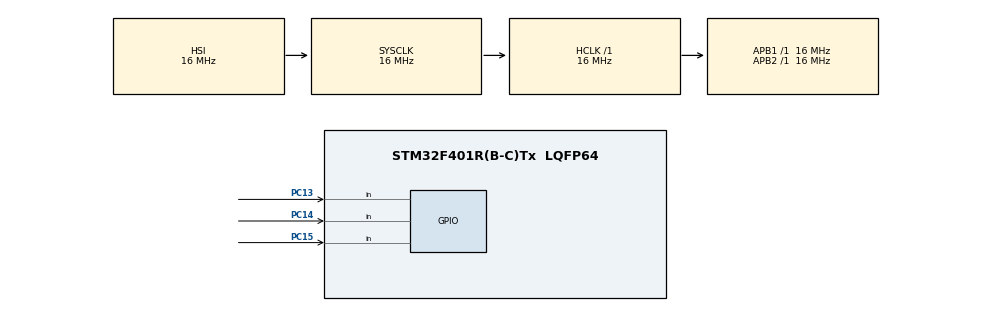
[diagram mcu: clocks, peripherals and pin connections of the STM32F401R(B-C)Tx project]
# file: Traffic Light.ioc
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FREERTOS.Tasks01=defaultTask,24,128,StartDefaultTask,Default,NULL,Dynamic,NULL,NULL
FREERTOS.configUSE_NEWLIB_REENTRANT=1
Mcu.Family=STM32F4
Mcu.Name=STM32F401R(B-C)Tx
Mcu.Package=LQFP64
NVIC.PriorityGroup=NVIC_PRIORITYGROUP_4
NVIC.TIM2_IRQn=true\:15\:0\:false\:false\:true\:false\:false\:true\:true
NVIC.TimeBase=TIM2_IRQn
NVIC.TimeBaseIP=TIM2
PC13-ANTI_TAMP.GPIO_PuPd=GPIO_PULLDOWN
PC13-ANTI_TAMP.Signal=GPIO_Input
PC14-OSC32_IN.GPIO_PuPd=GPIO_PULLDOWN
PC14-OSC32_IN.Signal=GPIO_Input
PC15-OSC32_OUT.GPIO_PuPd=GPIO_PULLDOWN
PC15-OSC32_OUT.Signal=GPIO_Input
ProjectManager.HeapSize=0x200
ProjectManager.StackSize=0x400
ProjectManager.TargetToolchain=STM32CubeIDE
RCC.AHBFreq_Value=16000000
RCC.APB1Freq_Value=16000000
RCC.APB1TimFreq_Value=16000000
RCC.APB2Freq_Value=16000000
RCC.APB2TimFreq_Value=16000000
RCC.CortexFreq_Value=16000000
RCC.HCLKFreq_Value=16000000
RCC.HSE_VALUE=25000000
RCC.HSI_VALUE=16000000
RCC.LSE_VALUE=32768
RCC.SYSCLKFreq_VALUE=16000000
RCC.VCOOutputFreq_Value=192000000
VP_FREERTOS_VS_CMSIS_V2.Mode=CMSIS_V2
VP_SYS_VS_tim2.Mode=TIM2
board=custom

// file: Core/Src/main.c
/* USER CODE BEGIN Header */
/**
  ******************************************************************************
  * @file           : main.c
  * @brief          : Main program body
  ******************************************************************************
  * @attention
  *
  * Copyright (c) 2024 STMicroelectronics.
  * All rights reserved.
  *
  * This software is licensed under terms that can be found in the LICENSE file
  * in the root directory of this software component.
  * If no LICENSE file comes with this software, it is provided AS-IS.
  *
  ******************************************************************************
  */
/* USER CODE END Header */
#include "main.h"
#include "cmsis_os.h"

/* USER CODE BEGIN Includes */
#include <LED_interface.h>
#include <SSD_interface.h>
#include <FreeRTOS.h>
#include <task.h>
/* USER CODE END Includes */

/* USER CODE BEGIN PTD */
typedef enum {
	GREEN = 0,
	YELLOW,
	RED,
	MANUAL_YELLOW,
	MANUAL_RED,
	MANUAL_GREEN
} TrafficLightState_t;
/* USER CODE END PTD */

/* USER CODE BEGIN PD */
#define GREEN_LIGHT_DURATION	6000
#define YELLOW_LIGHT_DURATION	2000
#define RED_LIGHT_DURATION		6000
#define GREEN_LED_PIN			GPIO_PIN_11
#define YELLOW_LED_PIN			GPIO_PIN_12
#define RED_LED_PIN				GPIO_PIN_15
#define LED_GPIO				GPIOA
#define MANUAL_MODE_PIN			GPIO_PIN_13
#define RED_MODE_PIN			GPIO_PIN_14
#define GREEN_MODE_PIN			GPIO_PIN_15
#define MANUAL_MODE_PORT		GPIOC
/* USER CODE END PD */

/* Definitions for defaultTask */
osThreadId_t defaultTaskHandle;
const osThreadAttr_t defaultTask_attributes = {
  .name = "defaultTask",
  .stack_size = 128 * 4,
  .priority = (osPriority_t) osPriorityNormal,
};
/* USER CODE BEGIN PV */
uint8_t seconds = 0;
TrafficLightState_t currentState = GREEN;
TaskHandle_t xTrafficLight, xTrafficTimer;
GPIO_PinState xMode = GPIO_PIN_RESET;
GPIO_PinState xRed = GPIO_PIN_RESET;
GPIO_PinState xGreen = GPIO_PIN_RESET;
/* USER CODE END PV */

void SystemClock_Config(void);
static void MX_GPIO_Init(void);
void StartDefaultTask(void *argument);

/* USER CODE BEGIN PFP */
void vTrafficMultiplexTimer(void *pvParameters);
void vTrafficLightTask(void *pvParameters);
void vTrafficTimer(void *pvParameters);
/* USER CODE END PFP */

int main(void)
{

  /* MCU Configuration--------------------------------------------------------*/

  /* Reset of all peripherals, Initializes the Flash interface and the Systick. */
  HAL_Init();

  /* Configure the system clock */
  SystemClock_Config();

  /* Initialize all configured peripherals */
  MX_GPIO_Init();
  /* USER CODE BEGIN 2 */
  LED_voidInit(LED_GPIO, GREEN_LED_PIN);
  LED_voidInit(LED_GPIO, YELLOW_LED_PIN);
  LED_voidInit(LED_GPIO, RED_LED_PIN);
  SSD_voidInit();

  xTaskCreate(vTrafficMultiplexTimer, "Traffic Multiplex", configMINIMAL_STACK_SIZE, NULL, 4, NULL);
  xTaskCreate(vTrafficLightTask, "Traffic Light", configMINIMAL_STACK_SIZE, NULL, 3, xTrafficLight);
  //xTaskCreate(vTrafficTimer, "Traffic Timer", configMINIMAL_STACK_SIZE, NULL, 2, xTrafficTimer);

  vTaskStartScheduler();
  /* USER CODE END 2 */

  /* Init scheduler */
  //osKernelInitialize();

  /* Create the thread(s) */
  /* creation of defaultTask */
  //defaultTaskHandle = osThreadNew(StartDefaultTask, NULL, &defaultTask_attributes);

  /* Start scheduler */
  //osKernelStart();

  /* We should never get here as control is now taken by the scheduler */

  /* Infinite loop */
  while (1)
  {

  }
}

void SystemClock_Config(void)
{
  RCC_OscInitTypeDef RCC_OscInitStruct = {0};
  RCC_ClkInitTypeDef RCC_ClkInitStruct = {0};

  /** Configure the main internal regulator output voltage
  */
  __HAL_RCC_PWR_CLK_ENABLE();
  __HAL_PWR_VOLTAGESCALING_CONFIG(PWR_REGULATOR_VOLTAGE_SCALE2);

  /** Initializes the RCC Oscillators according to the specified parameters
  * in the RCC_OscInitTypeDef structure.
  */
  RCC_OscInitStruct.OscillatorType = RCC_OSCILLATORTYPE_HSI;
  RCC_OscInitStruct.HSIState = RCC_HSI_ON;
  RCC_OscInitStruct.HSICalibrationValue = RCC_HSICALIBRATION_DEFAULT;
  RCC_OscInitStruct.PLL.PLLState = RCC_PLL_NONE;
  if (HAL_RCC_OscConfig(&RCC_OscInitStruct) != HAL_OK)
  {
    Error_Handler();
  }

  /** Initializes the CPU, AHB and APB buses clocks
  */
  RCC_ClkInitStruct.ClockType = RCC_CLOCKTYPE_HCLK|RCC_CLOCKTYPE_SYSCLK
                              |RCC_CLOCKTYPE_PCLK1|RCC_CLOCKTYPE_PCLK2;
  RCC_ClkInitStruct.SYSCLKSource = RCC_SYSCLKSOURCE_HSI;
  RCC_ClkInitStruct.AHBCLKDivider = RCC_SYSCLK_DIV1;
  RCC_ClkInitStruct.APB1CLKDivider = RCC_HCLK_DIV1;
  RCC_ClkInitStruct.APB2CLKDivider = RCC_HCLK_DIV1;

  if (HAL_RCC_ClockConfig(&RCC_ClkInitStruct, FLASH_LATENCY_0) != HAL_OK)
  {
    Error_Handler();
  }
}

static void MX_GPIO_Init(void)
{
  GPIO_InitTypeDef GPIO_InitStruct = {0};

  /* GPIO Ports Clock Enable */
  __HAL_RCC_GPIOC_CLK_ENABLE();

  /*Configure GPIO pins : PC13 PC14 PC15 */
  GPIO_InitStruct.Pin = GPIO_PIN_13|GPIO_PIN_14|GPIO_PIN_15;
  GPIO_InitStruct.Mode = GPIO_MODE_INPUT;
  GPIO_InitStruct.Pull = GPIO_PULLDOWN;
  HAL_GPIO_Init(GPIOC, &GPIO_InitStruct);

}

/* USER CODE BEGIN 4 */

void vTrafficMultiplexTimer(void *pvParameters){
	while(1){
		SSD_voidDisplayMultiplexedNumber((seconds / 2));
		vTaskDelay(pdMS_TO_TICKS(10));
	}

}

void vTrafficTimer(void *pvParameters){
	while (1){
		//if(xMode == GPIO_PIN_RESET){
			seconds++;
			vTaskDelay(pdMS_TO_TICKS(1000));

	}
}

void vTrafficLightTask(void *pvParameters) {

	while (1) {
		xMode = HAL_GPIO_ReadPin(MANUAL_MODE_PORT, MANUAL_MODE_PIN);
		xRed = HAL_GPIO_ReadPin(MANUAL_MODE_PORT, RED_MODE_PIN);
		xGreen = HAL_GPIO_ReadPin(MANUAL_MODE_PORT, GREEN_MODE_PIN);
		if(xMode == 1 && xRed == 1){
			currentState = MANUAL_RED;
		}
		else if (xMode == 1 && xGreen == 1){
			currentState = MANUAL_GREEN;
		}
		else if(xMode == 1){
			currentState = MANUAL_YELLOW;
		}
		else{

		}
		switch (currentState) {
			case GREEN:
			LED_voidOn(LED_GPIO, GREEN_LED_PIN, LED_FORWARD_CONNECTION);
			LED_voidOff(LED_GPIO, RED_LED_PIN, LED_FORWARD_CONNECTION);
			LED_voidOff(LED_GPIO, YELLOW_LED_PIN, LED_FORWARD_CONNECTION);
			if ((GREEN_LIGHT_DURATION / 1000) * 2 == seconds){
				currentState = RED;
				seconds = 0;
			}
			else{
				seconds++;
				vTaskDelay(pdMS_TO_TICKS(500));
			}
			break;

			case YELLOW:
				LED_voidOff(LED_GPIO, GREEN_LED_PIN, LED_FORWARD_CONNECTION);
				LED_voidOff(LED_GPIO, RED_LED_PIN, LED_FORWARD_CONNECTION);
				LED_voidOn(LED_GPIO, YELLOW_LED_PIN, LED_FORWARD_CONNECTION);
				if ((YELLOW_LIGHT_DURATION / 1000) * 2 == seconds){
					currentState = GREEN;
					seconds = 0;
				}
				else{
					seconds++;
					vTaskDelay(pdMS_TO_TICKS(500));
				}
				break;

			case RED:
				LED_voidOff(LED_GPIO, GREEN_LED_PIN, LED_FORWARD_CONNECTION);
				LED_voidOn(LED_GPIO, RED_LED_PIN, LED_FORWARD_CONNECTION);
				LED_voidOff(LED_GPIO, YELLOW_LED_PIN, LED_FORWARD_CONNECTION);
				if ((RED_LIGHT_DURATION / 1000) * 2 == seconds){
					currentState = YELLOW;
					seconds = 0;
				}
				else{
					seconds++;
					vTaskDelay(pdMS_TO_TICKS(500));
				}

				break;
			case MANUAL_RED:
				LED_voidOff(LED_GPIO, GREEN_LED_PIN, LED_FORWARD_CONNECTION);
				LED_voidOn(LED_GPIO, RED_LED_PIN, LED_FORWARD_CONNECTION);
				LED_voidOff(LED_GPIO, YELLOW_LED_PIN, LED_FORWARD_CONNECTION);
				currentState = GREEN;
				seconds = 0;
				break;
			case MANUAL_GREEN:
				LED_voidOn(LED_GPIO, GREEN_LED_PIN, LED_FORWARD_CONNECTION);
				LED_voidOff(LED_GPIO, RED_LED_PIN, LED_FORWARD_CONNECTION);
				LED_voidOff(LED_GPIO, YELLOW_LED_PIN, LED_FORWARD_CONNECTION);
				currentState = GREEN;
				seconds = 0;
				break;
			case MANUAL_YELLOW:
				LED_voidOff(LED_GPIO, GREEN_LED_PIN, LED_FORWARD_CONNECTION);
				LED_voidOff(LED_GPIO, RED_LED_PIN, LED_FORWARD_CONNECTION);
				LED_voidOn(LED_GPIO, YELLOW_LED_PIN, LED_FORWARD_CONNECTION);
				currentState = GREEN;
				seconds = 0;
				break;
			default:
				currentState = RED;
				seconds = 0;
				break;
		}

	}
}

/* USER CODE END 4 */

void StartDefaultTask(void *argument)
{
  for(;;)
  {
    osDelay(1);
  }
}

void HAL_TIM_PeriodElapsedCallback(TIM_HandleTypeDef *htim)
{
  if (htim->Instance == TIM2) {
    HAL_IncTick();
  }
}

void Error_Handler(void)
{
  __disable_irq();
  while (1)
  {
  }
}
